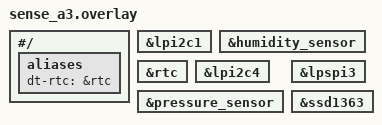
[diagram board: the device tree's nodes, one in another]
#/ {
  aliases {
    dt-rtc = &rtc;
  };
};

&lpi2c1 {
  status = "okay";
};

&humidity_sensor {
  status = "okay";
};

&rtc {
  status = "okay";
};

&lpi2c4 {
  status = "okay";
};

&pressure_sensor {
  status = "okay";
};

&lpspi3 {
  status = "okay";
};

&ssd1363 {
  status = "okay";
};
